AUTOSAR XML (schema 00050)
package /ComponentTypes
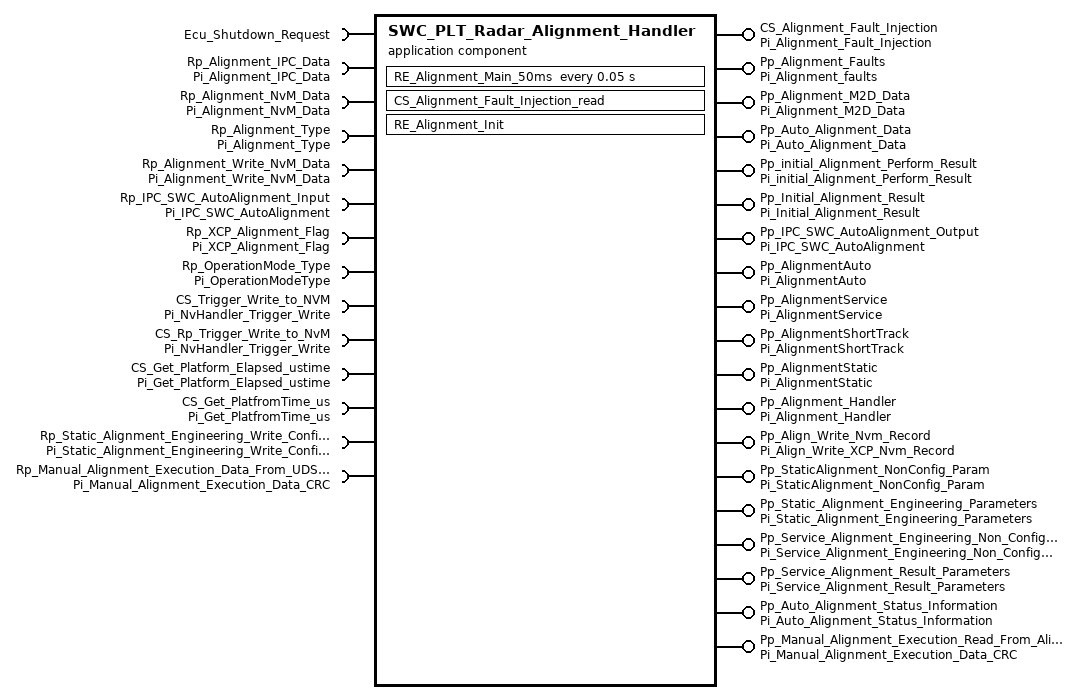
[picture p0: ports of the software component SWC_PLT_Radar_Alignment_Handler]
  application sw component type SWC_PLT_Radar_Alignment_Handler
    7 x provide port:
      CS_Alignment_Fault_Injection: server-com-spec{operation=read, queue-length=1}, provided-interface=Pi_Alignment_Fault_Injection
      Pp_Alignment_Faults: nonqueued-sender-com-spec{data-element=De_Alignment_Faults, init-value=constant-reference=C_Alignment_faults}, provided-interface=Pi_Alignment_faults
      Pp_Alignment_M2D_Data: nonqueued-sender-com-spec{data-element=De_Alignment_M2D_Data, init-value=fields=[{short-label=static_alignment_data, fields=[yaw:0, pitch:0, plate_angle_deg_scs:0, plate_distance:0, polarity:0, horz_angle_min:0, horz_angle_max:0, vert_angle_min:0, vert_angle_max:0, plate_lat_position:0, mount_loc:0, align_cmd:0, max_abs_misalignment_az:0, max_abs_misalignment_el_sky:0, max_abs_misalignment_el_ground:0, target_height_over_ground:0, k_num_valid_scan_needed:0, k_max_number_of_scans_allowed:0, target_range_rate:0, target_type_select:0, f_data_valid:0]}, {short-label=dynamic_alignment_data, fields=[0, 0, 0, max_abs_misalignment_az:0, short_track_target_height:0, short_track_target_range_rate:0, az_scf_kf_covariance:[0, 0, 0, 0], el_kf_covariance:0, iso_sensor_x_posn:0, iso_sensor_y_posn:0, iso_sensor_z_posn:0, iso_sensor_yaw:0, iso_sensor_pitch:0, iso_sensor_roll:0, distance_rear_axle_to_front_bumper:0, max_abs_misalignment_el_sky:0, max_abs_misalignment_el_ground:0, aacurrent_azimuth:0, aacurrent_elevation:0, 0, 0, mount_loc:0, short_track_exit_condition:0, f_data_valid:0, 0, 0, align_cmd:0, auto_align_status:0, 0, 0, el_roll_kf_covariance:[0, 0, 0, 0], Align_RadarOperation_Mode:0, coordinate_system_input:0]}]}, provided-interface=Pi_Alignment_M2D_Data
      Pp_Auto_Alignment_Data: nonqueued-sender-com-spec{data-element=Auto_Alignment_Data, init-value=constant-reference=C_Auto_Alignment_Result}, provided-interface=Pi_Auto_Alignment_Data
      Pp_initial_Alignment_Perform_Result: nonqueued-sender-com-spec{data-element=initial_Alignment_Perform, init-value=constant-reference=C_Initial_Alignment_Performance_Result}, provided-interface=Pi_initial_Alignment_Perform_Result
      Pp_Initial_Alignment_Result: nonqueued-sender-com-spec{data-element=Initial_Alignment_Result, init-value=constant-reference=C_Initial_Alignment_Result}, provided-interface=Pi_Initial_Alignment_Result
      Pp_IPC_SWC_AutoAlignment_Output: nonqueued-sender-com-spec{data-element=De_AutoAlignment, init-value=constant-reference=C_AutoAlignment_NvM_T}, provided-interface=Pi_IPC_SWC_AutoAlignment
    8 x require port:
      Ecu_Shutdown_Request: client-com-spec=Ecu_Shutdown_Request, required-interface=Ecu_Shutdown_Request
      Rp_Alignment_IPC_Data: nonqueued-receiver-com-spec{data-element=De_Alignment_IPC_Data, filter=data-filter-type=ALWAYS, init-value=fields=[{short-label=dra_core_log_data, fields=[vacs_boresight_az_estimated:0, vacs_boresight_el_estimated:0, estimated_standard_deviation_az:0, estimated_standard_deviation_el:0, alignment_complete_percent_az:0, alignment_complete_percent_el:0, total_time_since_start:0, total_time_running_az_scf:0, total_time_running_el:0, total_distance_since_start:0, total_distance_running_az_scf:0, total_distance_running_el:0, avg_spd_since_start:0, avg_spd_running_az_scf:0, avg_spd_running_el:0, estimated_pos_error_bound_az:0, estimated_pos_error_bound_el:0, estimated_neg_error_bound_az:0, estimated_neg_error_bound_el:0, speed_compensation_factor_estimated:0, n_updates_azimuth:0, n_updates_elevation:0, detection_used_az:24 x 0, detection_used_el:24 x 0, alignment_mode:0, error_status_detection_input:0, azimuth_estimation_qf:0, elevation_estimation_qf:0, error_status_az_est_out_of_bounds:0, error_status_el_est_out_of_bounds:0, 0, error_status_excessive_blockage:0, error_status_vehicle_input:0, detection_coordinate_system:0, error_status_scf_out_of_bounds:0, error_status_combined:0, error_status_interference:0, scf_estimation_qf:0, n_updates_roll:0, 0, vacs_boresight_roll_kf_internal:0, vacs_boresight_roll_estimated:0, el_roll_kf_covariance:[0, 0, 0, 0], alignment_index:0, vacs_boresight_az_kf_internal:0, vacs_boresight_el_kf_internal:0, estimated_standard_deviation_rl:0, estimated_pos_error_bound_rl:0, estimated_neg_error_bound_rl:0, num_cycles_since_well_converged:0, flag_well_converged_az_el:0, interference_detected:0, blockage_active:0, coordinate_system:0, error_status_sudden_state_change:0, error_status_parking_accident:0, vacs_boresight_az_nominal:0, vacs_boresight_el_nominal:0, error_status_trailer_detected:0]}, {short-label=sra_core_log_data, fields=[vacs_boresight_az_nominal:0, vacs_boresight_az_estimated:0, vacs_boresight_el_nominal:0, vacs_boresight_el_estimated:0, estimated_standard_deviation_az:0, estimated_standard_deviation_el:0, target_mean_azimuth:0, target_mean_elevation:0, target_mean_range:0, target_mean_r_dot:0, target_mean_raw_amp:0, target_mean_snr:0, target_std_dev_azimuth:0, target_std_dev_elevation:0, target_std_dev_range:0, target_std_dev_r_dot:0, target_std_dev_raw_amp:0, target_std_dev_snr:0, complete_percentage:0, n_updates_az_el:0, AlgoStatus:0, ErrorAzimuthEstimate:0, ErrorElevationEstimate:0, ErrorStatusInterference:0, ErrorStatusIntialisation:0, ErrorStatusDetection:0, ErrorStatusVehical:0, f_interference_detected:0, az_qf:0, el_qf:0, alignment_mode:0]}, {short-label=alignment_static, fields=[StatusOfPlate:0, StatusOfAzimuth:0, StatusOfElevation:0]}, {short-label=veh_info, fields=[veh_speed:0, veh_yaw:0, veh_speed_qf:0, veh_yaw_qf:0, lros_drive_reverse:0]}, {short-label=alignment_stream, fields=[horiz_misalign_ang:0, vert_misalign_ang:0, std_azimuth:0, std_elevation:0, meas_plate_range:0, meas_plate_r_dot:0, meas_plate_rcs:0, std_range:0, std_r_dot:0, complete_percentage:0, status_of_plate:0, status_horiz_misalign_ang:0, status_vert_misalign_ang:0]}, alignment_mode:0, interference_detected:0, blockage_active:0, operation_mode_status:0, data_qualifier:0, look_index:0]}, required-interface=Pi_Alignment_IPC_Data
      Rp_Alignment_NvM_Data: nonqueued-receiver-com-spec{data-element=Alignment_NvM_Data, filter=data-filter-type=ALWAYS, init-value=constant-reference=C_Write_Alignment_NvM_Data}, required-interface=Pi_Alignment_NvM_Data
      Rp_Alignment_Type: nonqueued-receiver-com-spec{data-element=Alignment_Type, filter=data-filter-type=ALWAYS, init-value=0}, required-interface=Pi_Alignment_Type
      Rp_Alignment_Write_NvM_Data: nonqueued-receiver-com-spec{data-element=Write_Alignment_NvM, filter=data-filter-type=ALWAYS, init-value=constant-reference=C_Write_Alignment_NvM_Data}, required-interface=Pi_Alignment_Write_NvM_Data
      Rp_IPC_SWC_AutoAlignment_Input: nonqueued-receiver-com-spec{data-element=De_AutoAlignment, filter=data-filter-type=ALWAYS, init-value=constant-reference=C_AutoAlignment_NvM_T}, required-interface=Pi_IPC_SWC_AutoAlignment
      Rp_XCP_Alignment_Flag: nonqueued-receiver-com-spec{data-element=De_XCP_Alignment_Flag, filter=data-filter-type=ALWAYS, init-value=85}, required-interface=Pi_XCP_Alignment_Flag
      Rp_OperationMode_Type: nonqueued-receiver-com-spec{data-element=De_OperationMode_System, filter=data-filter-type=ALWAYS, init-value=0}, required-interface=Pi_OperationModeType
    6 x provide port:
      Pp_AlignmentAuto: nonqueued-sender-com-spec{data-element=De_AlignmentAuto, init-value=fields=[StartAzimuth:0, StartElevation:0, AACurrentAzimuth:0, AACurrentElevation:0, AAAzimuthStd:0, AAElevationStd:0, AARollStd:0, Az_Err_positive:0, Az_Err_negative:0, El_Err_positive:0, El_Err_negative:0, RollError_positive:0, RollError_negative:0, HostScf:0, AzimuthNumUpdates:0, ElevationNumUpdates:0, AutoAlignmentFailRootCause:0, AlignAutoStatus:0, HostScf_QF:0, StartRoll:0, AACurrentRoll:0, RollUpdates:0]}, provided-interface=Pi_AlignmentAuto
      Pp_AlignmentService: nonqueued-sender-com-spec{data-element=De_AlignmentService, init-value=fields=[DistanceAbsolute:0, DistanceEffective:0, AvgNumOfDet:0, DurationAbsolute:0, DurationEffective:0, AverageSpeed:0, AlignmentServiceSt:0, VehicleCondition:0]}, provided-interface=Pi_AlignmentService
      Pp_AlignmentShortTrack: nonqueued-sender-com-spec{data-element=De_AlignmentShortTrack, init-value=fields=AlignShortTrackSt:0}, provided-interface=Pi_AlignmentShortTrack
      Pp_AlignmentStatic: nonqueued-sender-com-spec{data-element=De_AlignmentStatic, init-value=fields=[MeasuredAzimuth:0, MeasuredElevation:0, Measured_Az_Std:0, Measured_El_Std:0, MeasuredRange:0, MeasuredRangeStd:0, MeasuredRangeRate:0, MeasuredRangeRateStd:0, MeasuredAmplitude:0, MeasuredAmpStd:0, AlignmentStaticStatus:0, StatusOfPlate:0, StatusOfAzimuth:0, StatusOfElevation:0, ImpactByInterference:0]}, provided-interface=Pi_AlignmentStatic
      Pp_Alignment_Handler: nonqueued-sender-com-spec{data-element=De_Alignment_Handler, init-value=fields=[0, 0, 0, 0, 0, AlignmentAzimuth:0, AlignmentElevation:0, AzimuthStd:0, ElevationStd:0, calTime:0, CalDisplay:0, ProgressPercent:0, AlignmentError:0, ElevationQuality:0, AzimuthQuality:0, Alignment_modeIn:0, AlignmentModeOut:0, 0, Radar_Type_Input:0, CoordinateSystem_Input:0, 0, 0, AlignmentRoll:0, RollStd:0]}, provided-interface=Pi_Alignment_Handler
      Pp_Align_Write_Nvm_Record: nonqueued-sender-com-spec{data-element=Alignment_Record, init-value=fields=[AACurrentAzimuth:0, AACurrentElevation:0, AACurrentRoll:0, 0, 0, 0, 0, ElevationUpdates:0, AzimuthUpdates:0, RollUpdates:0, 0, 0, HostSpeedCompensationFactor:0, 0, 0, AlignmentModeOut:0, azimuth_estimation_qf:0, elevation_estimation_qf:0, scf_estimation_qf:0]}, provided-interface=Pi_Align_Write_XCP_Nvm_Record
    4 x require port:
      CS_Trigger_Write_to_NVM: client-com-spec=NvHandler_Trigger_Write_To_NVM, required-interface=Pi_NvHandler_Trigger_Write
      CS_Rp_Trigger_Write_to_NvM: client-com-spec=NvHandler_Trigger_Write_To_NVM, required-interface=Pi_NvHandler_Trigger_Write
      CS_Get_Platform_Elapsed_ustime: client-com-spec=read, required-interface=Pi_Get_Platform_Elapsed_ustime
      CS_Get_PlatfromTime_us: client-com-spec=read, required-interface=Pi_Get_PlatfromTime_us
    provide port Pp_StaticAlignment_NonConfig_Param: nonqueued-sender-com-spec{data-element=De_DID_StaticAlignment_NonConfig_Param_T, init-value=fields=[AlignmentStatic_NumberOfScans:0, AlignmentStatic_RangeOffset_Threshold:0, RangeRateUpper_Threshold:0, RCS_Min:0, RCS_Max:0, Velocity_Max:0, Yaw_Max:0, FlatPlateWidth_Lower_Limit:0, FlatPlateWidth_Upper_Limit:0, FlatPlateHeight_Lower_Limit:0, FlatPlateHeight_Upper_Limit:0, FlatPlateRCS_Lower_Limit:0, FlatPlateRCS_Upper_Limit:0, FlatPlateRange_Lower_Limit:0, FlatPlateRange_Upper_Limit:0, FlatPlateAzimuth_Lower_Limit:0, FlatPlateAzimuth_Upper_Limit:0, FlatPlateElevation_Lower_Limit:0, FlatPlateElevation_Upper_Limit:0, FlatPlateRangeRate_Lower_Limit:0, FlatPlateRangeRate_Upper_Limit:0]}, provided-interface=Pi_StaticAlignment_NonConfig_Param
    provide port Pp_Static_Alignment_Engineering_Parameters: nonqueued-sender-com-spec{data-element=De_Static_Alignment_Engineering_Parameters, init-value=fields=[AlignmentStatic_AzimuthUpper_Threshold:0, AlignmentStatic_AzimuthLower_Threshold:0, AlignmentStatic_ElevationUpper_Threshold:0, AlignmentStatic_ElevationLower_Threshold:0, AlignmentStatic_TargetAzimuth:0, AlignmentStatic_TargetElevation:0, AlignmentStatic_TargetDistance:0]}, provided-interface=Pi_Static_Alignment_Engineering_Parameters
    require port Rp_Static_Alignment_Engineering_Write_Configuration_Parameters_CRC: nonqueued-receiver-com-spec{data-element=De_Static_Alignment_Engineering_Write_Configuration_Parameters_CRC, filter=data-filter-type=ALWAYS, init-value=fields=[{short-label=Static_alignment_write_Params, fields=[AlignmentStatic_TargetAzimuth:0, AlignmentStatic_TargetElevation:0, AlignmentStatic_TargetDistance:120]}, Data_CRC:0]}, required-interface=Pi_Static_Alignment_Engineering_Write_Configuration_Parameters_CRC
    4 x provide port:
      Pp_Service_Alignment_Engineering_Non_Configuration_Parameters: nonqueued-sender-com-spec{data-element=De_Service_Alignment_Engineering_Non_Configuration_Parameters, init-value=fields=[AlignService_Abs_Dist_Th:0, AlignService_Eff_Dist_Th:0, AlignService_Abs_Duration_Th:0, AlignService_Eff_Duration_Th:0, AlignService_Vel_Min:0, AlignService_Vel_Max:0, AlignService_Yawrate_Max:0]}, provided-interface=Pi_Service_Alignment_Engineering_Non_Configuration_Parameters
      Pp_Service_Alignment_Result_Parameters: nonqueued-sender-com-spec{data-element=De_Service_Alignment_Result_Parameters, init-value=fields=[AlignmentModeOut:0, AlignmentServiceStatus:0, AlignmentError:0, AlignmentAzimuth:0, AlignmentElevation:0, AlignmentRoll:0, AzimuthStd:0, ElevationStd:0, RollStd:0, CalTime:0, ProgressPercent:0, CalDisplay:0, 0, 0, 0, 0, VehicleCondition:0, AverageNumberOfDetections:0, AverageSpeed:0, DistanceAbsolute:0, DistanceEffective:0, DurationAbsolute:0, DurationEffective:0, 0, 0, 0, 0]}, provided-interface=Pi_Service_Alignment_Result_Parameters
      Pp_Auto_Alignment_Status_Information: nonqueued-sender-com-spec{data-element=De_Auto_Alignment_Status_Information, init-value=fields=[AlignmentModeOut:0, AlignmentAutoStatus:0, AutoAlignmentFailRootCause:0, StartAzimuth:0, StartElevation:0, StartRoll:0, AACurrentAzimuth:0, AACurrentElevation:0, AACurrentRoll:0, AAAzimuthStd:0, AAElevationStd:0, AARollStd:0, 0, 0, 0, 0, AzimuthError_positive:0, ElevationError_positive:0, RollError_positive:0, AzimuthError_negative:0, ElevationError_negative:0, RollError_negative:0, HostSpeedCompensationFactor:0, HostSpeedCompensationFactor_QF:0, AzimuthUpdates:0, ElevationUpdates:0, RollUpdates:0]}, provided-interface=Pi_Auto_Alignment_Status_Information
      Pp_Manual_Alignment_Execution_Read_From_Alignment_Data_CRC: nonqueued-sender-com-spec{data-element=De_Manual_Alignment_Execution_Data_CRC, init-value=fields=[{short-label=Manual_Alignment_Execution_Data, fields=[AlignmentModeIn:0, 0, IntialMisalignmentAngleAzimuth:0, IntialMisalignmentAngleElevation:0]}, Data_CRC:0]}, provided-interface=Pi_Manual_Alignment_Execution_Data_CRC
    require port Rp_Manual_Alignment_Execution_Data_From_UDS_CRC: nonqueued-receiver-com-spec{data-element=De_Manual_Alignment_Execution_Data_CRC, filter=data-filter-type=ALWAYS, init-value=fields=[{short-label=Manual_Alignment_Execution_Data, fields=[AlignmentModeIn:0, 0, IntialMisalignmentAngleAzimuth:0, IntialMisalignmentAngleElevation:0]}, Data_CRC:0]}, required-interface=Pi_Manual_Alignment_Execution_Data_CRC
    behavior SWC_PLT_Radar_Alignment_Handler_InternalBehavior: handle-termination-and-restart=NO-SUPPORT
      operation invoked event OIT_CS_Alignment_Fault_Injection_read_CS_Alignment_Fault_Injection_read: start-on-event=CS_Alignment_Fault_Injection_read, operation=CS_Alignment_Fault_Injection.read
      init event SWC_Appl_Alignment_InitEvent: start-on-event=RE_Alignment_Init
      timing event TMT_Runnable: start-on-event=RE_Alignment_Main_50ms, period=0.05
      per-instance-parameters:
        parameter data prototype Appl_AutoAlignment_DefaultValue: sw-calibration-access=READ-WRITE, type=Dt_Alignment_NVM_T, init-value=constant-reference=C_AutoAlignment_NvM_T
      port-api-options:
        enable-take-address=true, error-handling=NO-TRANSFORMER-ERROR-HANDLING, indirect-api=false, port=Pp_Align_Write_Nvm_Record
        enable-take-address=true, error-handling=NO-TRANSFORMER-ERROR-HANDLING, indirect-api=false, port=CS_Trigger_Write_to_NVM
      runnable CS_Alignment_Fault_Injection_read
      runnable RE_Alignment_Init
        data-receive-point-by-arguments:
          access REC_Rp_Alignment_NvM_Data_Alignment_NvM_Data: accessed-variable=Rp_Alignment_NvM_Data.Alignment_NvM_Data
      runnable RE_Alignment_Main_50ms
        data-receive-point-by-arguments:
          9 x access:
            REC_Rp_Alignment_IPC_Data_De_Alignment_IPC_Data: accessed-variable=Rp_Alignment_IPC_Data.De_Alignment_IPC_Data
            REC_Rp_Alignment_Type_Alignment_Type: accessed-variable=Rp_Alignment_Type.Alignment_Type
            REC_Rp_Alignment_Write_NvM_Data_Write_Alignment_NvM: accessed-variable=Rp_Alignment_Write_NvM_Data.Write_Alignment_NvM
            REC_Rp_IPC_SWC_AutoAlignment_Input_De_AutoAlignment: accessed-variable=Rp_IPC_SWC_AutoAlignment_Input.De_AutoAlignment
            REC_Rp_XCP_Alignment_Flag_De_XCP_Alignment_Flag: accessed-variable=Rp_XCP_Alignment_Flag.De_XCP_Alignment_Flag
            REC_Rp_OperationMode_Type_De_OperationMode_System: accessed-variable=Rp_OperationMode_Type.De_OperationMode_System
            REC_Rp_Alignment_NvM_Data_Alignment_NvM_Data: accessed-variable=Rp_Alignment_NvM_Data.Alignment_NvM_Data
            REC_Rp_Static_Alignment_Engineering_Write_Configuration_Parameters_CRC_De_Static_Alignment_Engineering_Write_Configurati6C102BA0: accessed-variable=Rp_Static_Alignment_Engineering_Write_Configuration_Parameters_CRC.De_Static_Alignment_Engineering_Write_Configuration_Parameters_CRC
            REC_Rp_Manual_Alignment_Execution_Data_From_UDS_CRC_De_Manual_Alignment_Execution_Data_CRC: accessed-variable=Rp_Manual_Alignment_Execution_Data_From_UDS_CRC.De_Manual_Alignment_Execution_Data_CRC
        data-send-points:
          18 x access:
            SEND_Pp_Alignment_faults_De_Alignment_Faults: accessed-variable=Pp_Alignment_Faults.De_Alignment_Faults
            SEND_Pp_Alignment_M2D_Data_De_Alignment_M2D_Data: accessed-variable=Pp_Alignment_M2D_Data.De_Alignment_M2D_Data
            SEND_Pp_Auto_Alignment_Data_Auto_Alignment_Data: accessed-variable=Pp_Auto_Alignment_Data.Auto_Alignment_Data
            SEND_Pp_initial_Alignment_Perform_Result_initial_Alignment_Perform: accessed-variable=Pp_initial_Alignment_Perform_Result.initial_Alignment_Perform
            SEND_Pp_Initial_Alignment_Result_Initial_Alignment_Result: accessed-variable=Pp_Initial_Alignment_Result.Initial_Alignment_Result
            SEND_Pp_IPC_SWC_AutoAlignment_Output_De_AutoAlignment: accessed-variable=Pp_IPC_SWC_AutoAlignment_Output.De_AutoAlignment
            SEND_Pp_AlignmentAuto_De_AlignmentAuto: accessed-variable=Pp_AlignmentAuto.De_AlignmentAuto
            SEND_Pp_AlignmentService_De_AlignmentService: accessed-variable=Pp_AlignmentService.De_AlignmentService
            SEND_Pp_AlignmentShortTrack_De_AlignmentShortTrack: accessed-variable=Pp_AlignmentShortTrack.De_AlignmentShortTrack
            SEND_Pp_AlignmentStatic_De_AlignmentStatic: accessed-variable=Pp_AlignmentStatic.De_AlignmentStatic
            SEND_Pp_Alignment_Handler_De_Alignment_Handler: accessed-variable=Pp_Alignment_Handler.De_Alignment_Handler
            SEND_Pp_Align_Write_Nvm_Record_Alignment_Record: accessed-variable=Pp_Align_Write_Nvm_Record.Alignment_Record
            SEND_Pp_StaticAlignment_NonConfig_Param_De_DID_StaticAlignment_NonConfig_Param_T: accessed-variable=Pp_StaticAlignment_NonConfig_Param.De_DID_StaticAlignment_NonConfig_Param_T
            SEND_Pp_Static_Alignment_Engineering_Parameters_De_Static_Alignment_Engineering_Parameters: accessed-variable=Pp_Static_Alignment_Engineering_Parameters.De_Static_Alignment_Engineering_Parameters
            SEND_Pp_Service_Alignment_Engineering_Non_Configuration_Parameters_De_Service_Alignment_Engineering_Non_Configuration_Parameters: accessed-variable=Pp_Service_Alignment_Engineering_Non_Configuration_Parameters.De_Service_Alignment_Engineering_Non_Configuration_Parameters
            SEND_Pp_Service_Alignment_Result_Parameters_De_Service_Alignment_Result_Parameters: accessed-variable=Pp_Service_Alignment_Result_Parameters.De_Service_Alignment_Result_Parameters
            SEND_Pp_Auto_Alignment_Status_Information_De_Auto_Alignment_Status_Information: accessed-variable=Pp_Auto_Alignment_Status_Information.De_Auto_Alignment_Status_Information
            SEND_Pp_Manual_Alignment_Execution_Read_From_Alignment_Data_CRC_De_Manual_Alignment_Execution_Data_CRC: accessed-variable=Pp_Manual_Alignment_Execution_Read_From_Alignment_Data_CRC.De_Manual_Alignment_Execution_Data_CRC
        5 x sync call:
          SC_Ecu_Shutdown_Request_Ecu_Shutdown_Request: operation=Ecu_Shutdown_Request.Ecu_Shutdown_Request
          SC_CS_Trigger_Write_to_NVM_NvHandler_Trigger_Write_To_NVM: operation=CS_Trigger_Write_to_NVM.NvHandler_Trigger_Write_To_NVM
          SC_CS_Rp_Trigger_Write_to_NvM_NvHandler_Trigger_Write_To_NVM: operation=CS_Rp_Trigger_Write_to_NvM.NvHandler_Trigger_Write_To_NVM
          SC_CS_Get_Platform_Elapsed_ustime_read: operation=CS_Get_Platform_Elapsed_ustime.read
          SC_CS_Get_PlatfromTime_us_read: operation=CS_Get_PlatfromTime_us.read
  swc implementation SWC_PLT_Radar_Alignment_Handler_Implementation: behavior=SWC_PLT_Radar_Alignment_Handler_InternalBehavior
    code-descriptors:
      code Default: artifact-descriptors=autosar-engineering-object=category=SWSRC
